AUTOSAR XML (schema 321)
package /ComponentType
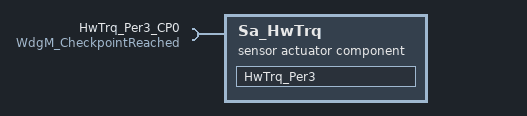
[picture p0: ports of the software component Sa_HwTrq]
  sensor actuator software component type Sa_HwTrq
    require port HwTrq_Per3_CP0: client-com-spec=CheckpointReached, required-interface=WdgM_CheckpointReached
  internal behavior Sa_HwTrq_InternalBehavior: component=Sa_HwTrq, port-api-option{enable-take-address=false, indirect-api=false, port=HwTrq_Per3_CP0}
    runnable HwTrq_Per3
      sync call SC_HwTrq_Per3_CP0_CheckpointReached: operation=HwTrq_Per3_CP0.CheckpointReached, timeout=0
  swc implementation Sa_HwTrq_Implementation: behavior=Sa_HwTrq_InternalBehavior
    code-descriptors:
      code Code: type=SRC
package /PortInterface
  client server interface WdgM_CheckpointReached: is-service=true
    operation CheckpointReached: possible-error=E_NOT_OK  # Indicates to the Watchdog Manager that a Checkpoint within a Supervised Entity has been reached.
    error E_NOT_OK: error-code=1
